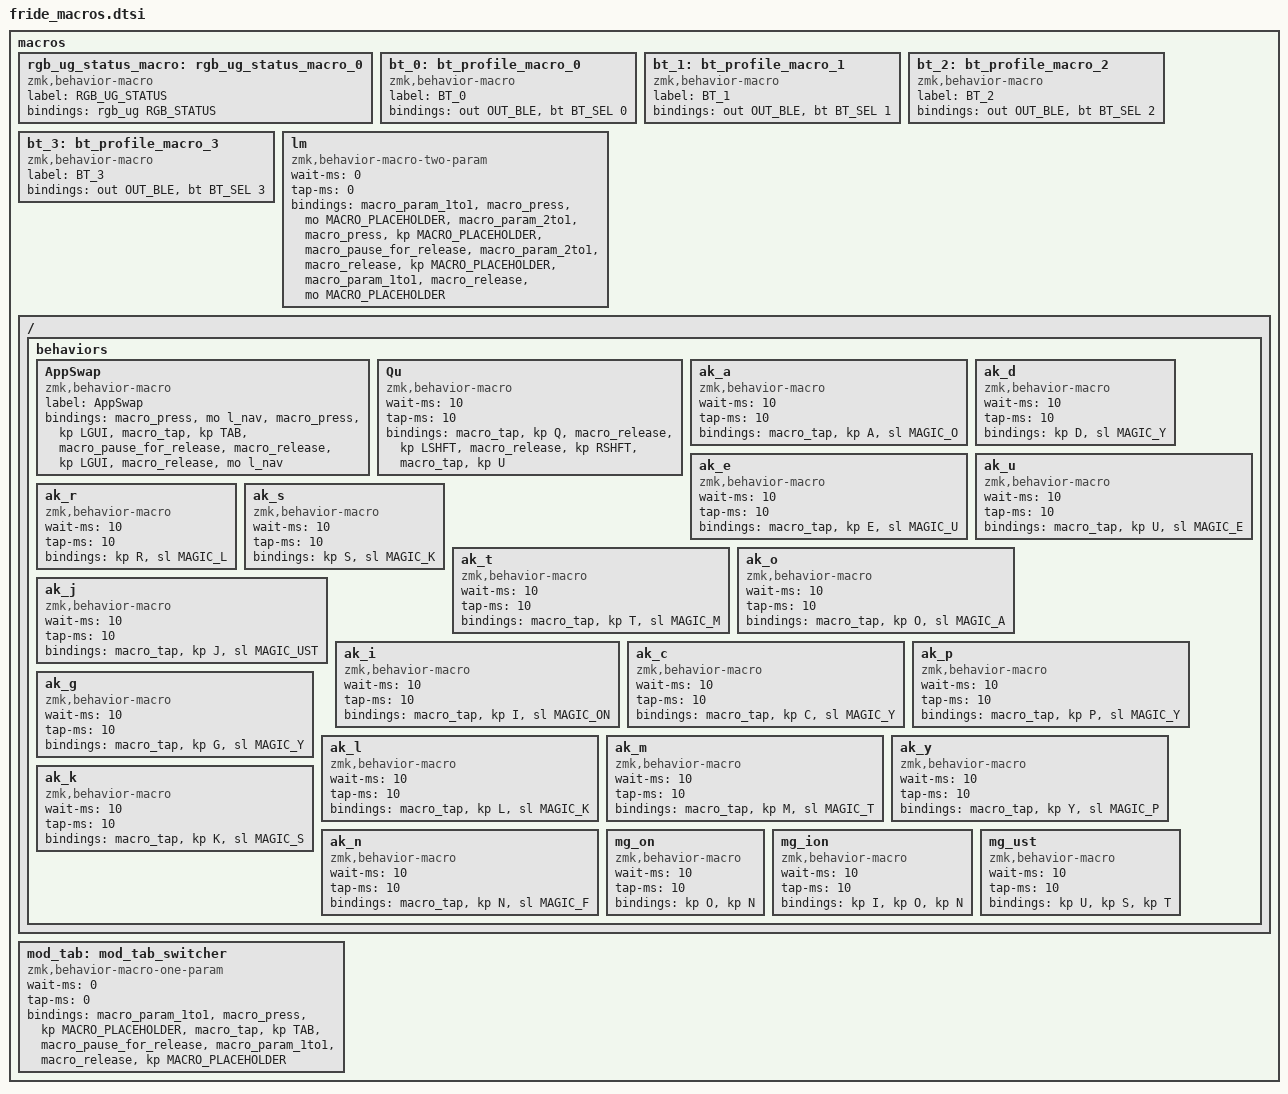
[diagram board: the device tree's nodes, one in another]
 macros {
    rgb_ug_status_macro: rgb_ug_status_macro_0 {
        label = "RGB_UG_STATUS";
        compatible = "zmk,behavior-macro";
        #binding-cells = <0>;
        bindings
            = <&rgb_ug RGB_STATUS>;
    };

    bt_0: bt_profile_macro_0 {
        label = "BT_0";
        compatible = "zmk,behavior-macro";
        #binding-cells = <0>;
        bindings
            = <&out OUT_BLE>,
              <&bt BT_SEL 0>;
    };

    bt_1: bt_profile_macro_1 {
        label = "BT_1";
        compatible = "zmk,behavior-macro";
        #binding-cells = <0>;
        bindings
            = <&out OUT_BLE>,
              <&bt BT_SEL 1>;
    };

    bt_2: bt_profile_macro_2 {
        label = "BT_2";
        compatible = "zmk,behavior-macro";
        #binding-cells = <0>;
        bindings
            = <&out OUT_BLE>,
              <&bt BT_SEL 2>;
    };

    bt_3: bt_profile_macro_3 {
        label = "BT_3";
        compatible = "zmk,behavior-macro";
        #binding-cells = <0>;
        bindings
            = <&out OUT_BLE>,
              <&bt BT_SEL 3>;
    };
    
    
    /**
    * Temporarily switches to a layer (`&mo`) while a modifier is held.
    * Analogous to QMK's `LM()`, using a parameterized macro.
    *
    * Params:
    *  1. Layer to switch to
    *  2. Modifier to press while layer is active
    *
    * Example:
    *  `&lm NUM_LAYER LSHIFT`
    */
    lm: lm {
        compatible = "zmk,behavior-macro-two-param";
        wait-ms = <0>;
        tap-ms = <0>;
        #binding-cells = <2>;
        bindings
            = <&macro_param_1to1>
            , <&macro_press &mo MACRO_PLACEHOLDER>
            , <&macro_param_2to1>
            , <&macro_press &kp MACRO_PLACEHOLDER>
            , <&macro_pause_for_release>
            , <&macro_param_2to1>
            , <&macro_release &kp MACRO_PLACEHOLDER>
            , <&macro_param_1to1>
            , <&macro_release &mo MACRO_PLACEHOLDER>
            ;
    };

    ZMK_MACRO(AppSwap,
            label = "AppSwap";                        
            bindings 
            = <&macro_press &mo l_nav>
            , <&macro_press &kp LGUI>
            , <&macro_tap &kp TAB>
            , <&macro_pause_for_release>        
            , <&macro_release &kp LGUI>
            , <&macro_release &mo l_nav>
            ;
    )            

    ZMK_MACRO(Qu,
        wait-ms = <10>;
        tap-ms = <10>;
        bindings = <&macro_tap &kp Q>
                , <&macro_release &kp LSHFT>
                , <&macro_release &kp RSHFT>
                , <&macro_tap &kp U>
                ;
    )



    mod_tab: mod_tab_switcher {
        compatible = "zmk,behavior-macro-one-param";
        wait-ms = <0>;
        tap-ms = <0>;
        #binding-cells = <1>;
        bindings
            = <&macro_param_1to1>
            , <&macro_press &kp MACRO_PLACEHOLDER>
            , <&macro_tap &kp TAB>
            , <&macro_pause_for_release>
            , <&macro_param_1to1>
            , <&macro_release &kp MACRO_PLACEHOLDER>
            ;
    };

    //// magic
     ZMK_MACRO(ak_a,
        wait-ms = <10>;
        tap-ms = <10>;
        bindings = <&macro_tap &kp A>
                 , <&sl MAGIC_O>;
    )
    ZMK_MACRO(ak_d,
        wait-ms = <10>;
        tap-ms = <10>;
        bindings =<&kp D &sl MAGIC_Y>;
    )

     ZMK_MACRO(ak_e,
        wait-ms = <10>;
        tap-ms = <10>;
        bindings = <&macro_tap &kp E>
                 , <&sl MAGIC_U>;
    )
    ZMK_MACRO(ak_u,
        wait-ms = <10>;
        tap-ms = <10>;
        bindings = <&macro_tap &kp U>
                 , <&sl MAGIC_E>;
    )
    ZMK_MACRO(ak_r,
        wait-ms = <10>;
        tap-ms = <10>;
        bindings = <&kp R &sl MAGIC_L>;
    )
    ZMK_MACRO(ak_s,
        wait-ms = <10>;
        tap-ms = <10>;
        bindings = <&kp S &sl MAGIC_K>;
    )

    ZMK_MACRO(ak_t,
        wait-ms = <10>;
        tap-ms = <10>;
        bindings = <&macro_tap &kp T>
                 , <&sl MAGIC_M>;
    )

    ZMK_MACRO(ak_o,
        wait-ms = <10>;
        tap-ms = <10>;
        bindings = <&macro_tap &kp O>
                 , <&sl MAGIC_A>;
    )
    ZMK_MACRO(ak_j,
        wait-ms = <10>;
        tap-ms = <10>;
        bindings = <&macro_tap &kp J>
                 , <&sl MAGIC_UST>;
    )
    ZMK_MACRO(ak_i,
        wait-ms = <10>;
        tap-ms = <10>;
        bindings = <&macro_tap &kp I>
                 , <&sl MAGIC_ON>;
    )
    ZMK_MACRO(ak_c,
        wait-ms = <10>;
        tap-ms = <10>;
        bindings = <&macro_tap &kp C>
                 , <&sl MAGIC_Y>;
    )
    ZMK_MACRO(ak_p,
        wait-ms = <10>;
        tap-ms = <10>;
        bindings = <&macro_tap &kp P>
                 , <&sl MAGIC_Y>;
    )
    ZMK_MACRO(ak_g,
        wait-ms = <10>;
        tap-ms = <10>;
        bindings = <&macro_tap &kp G>
                 , <&sl MAGIC_Y>;
    )
    ZMK_MACRO(ak_l,
        wait-ms = <10>;
        tap-ms = <10>;
        bindings = <&macro_tap &kp L>
                 , <&sl MAGIC_K>;
    )
    ZMK_MACRO(ak_m,
        wait-ms = <10>;
        tap-ms = <10>;
        bindings = <&macro_tap &kp M>
                 , <&sl MAGIC_T>;
    )
    ZMK_MACRO(ak_y,
        wait-ms = <10>;
        tap-ms = <10>;
        bindings = <&macro_tap &kp Y>
                 , <&sl MAGIC_P>;
    )
    ZMK_MACRO(ak_k,
        wait-ms = <10>;
        tap-ms = <10>;
        bindings = <&macro_tap &kp K>
                 , <&sl MAGIC_S>;
    )
    ZMK_MACRO(ak_n,
        wait-ms = <10>;
        tap-ms = <10>;
        bindings = <&macro_tap &kp N>
                 , <&sl MAGIC_F>;
    )

    // 
    ZMK_MACRO(mg_on,
        wait-ms = <10>;
        tap-ms = <10>;
        bindings = <&kp O &kp N>;
    )
    ZMK_MACRO(mg_ion,
        wait-ms = <10>;
        tap-ms = <10>;
        bindings = <&kp I &kp O &kp N>;
    )
    ZMK_MACRO(mg_ust,
        wait-ms = <10>;
        tap-ms = <10>;
        bindings = <&kp U &kp S &kp T>;
    )

 };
